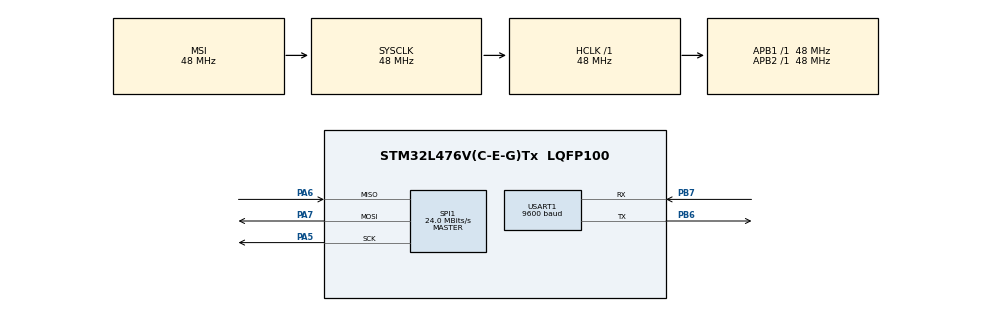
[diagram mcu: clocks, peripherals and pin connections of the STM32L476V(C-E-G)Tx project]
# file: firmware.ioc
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Mcu.Family=STM32L4
Mcu.Name=STM32L476V(C-E-G)Tx
Mcu.Package=LQFP100
NVIC.PriorityGroup=NVIC_PRIORITYGROUP_4
PA5.Mode=Full_Duplex_Master
PA5.Signal=SPI1_SCK
PA6.Mode=Full_Duplex_Master
PA6.Signal=SPI1_MISO
PA7.Mode=Full_Duplex_Master
PA7.Signal=SPI1_MOSI
PB6.Mode=Asynchronous
PB6.Signal=USART1_TX
PB7.Mode=Asynchronous
PB7.Signal=USART1_RX
PH0/OSC_IN.Mode=HSE-External-Oscillator
PH0/OSC_IN.Signal=RCC_OSC_IN
PH1/OSC_OUT.Mode=HSE-External-Oscillator
PH1/OSC_OUT.Signal=RCC_OSC_OUT
ProjectManager.HeapSize=0x200
ProjectManager.StackSize=0x400
ProjectManager.TargetToolchain=TrueSTUDIO
RCC.ADCFreq_Value=32000000
RCC.AHBFreq_Value=48000000
RCC.APB1Freq_Value=48000000
RCC.APB1TimFreq_Value=48000000
RCC.APB2Freq_Value=48000000
RCC.APB2TimFreq_Value=48000000
RCC.CortexFreq_Value=48000000
RCC.HCLKFreq_Value=48000000
RCC.HSE_VALUE=8000000
RCC.HSI_VALUE=16000000
RCC.LSE_VALUE=32768
RCC.MSIClockRange=RCC_MSIRANGE_11
RCC.MSI_VALUE=48000000
RCC.PLLSourceVirtual=RCC_PLLSOURCE_HSE
RCC.PREFETCH_ENABLE=1
RCC.SYSCLKFreq_VALUE=48000000
RCC.USBFreq_Value=32000000
RCC.VCOOutputFreq_Value=64000000
SPI1.CalculateBaudRate=24.0 MBits/s
SPI1.Mode=SPI_MODE_MASTER
USART1.BaudRate=9600
USART1.WordLength=UART_WORDLENGTH_8B
board=STM32L476G-DISCO

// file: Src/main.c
/**
  ******************************************************************************
  * File Name          : main.c
  * Description        : Main program body
  ******************************************************************************
  *
  * COPYRIGHT(c) 2017 STMicroelectronics
  *
  * Redistribution and use in source and binary forms, with or without modification,
  * are permitted provided that the following conditions are met:
  *   1. Redistributions of source code must retain the above copyright notice,
  *      this list of conditions and the following disclaimer.
  *   2. Redistributions in binary form must reproduce the above copyright notice,
  *      this list of conditions and the following disclaimer in the documentation
  *      and/or other materials provided with the distribution.
  *   3. Neither the name of STMicroelectronics nor the names of its contributors
  *      may be used to endorse or promote products derived from this software
  *      without specific prior written permission.
  *
  * THIS SOFTWARE IS PROVIDED BY THE COPYRIGHT HOLDERS AND CONTRIBUTORS "AS IS"
  * AND ANY EXPRESS OR IMPLIED WARRANTIES, INCLUDING, BUT NOT LIMITED TO, THE
  * IMPLIED WARRANTIES OF MERCHANTABILITY AND FITNESS FOR A PARTICULAR PURPOSE ARE
  * DISCLAIMED. IN NO EVENT SHALL THE COPYRIGHT HOLDER OR CONTRIBUTORS BE LIABLE
  * FOR ANY DIRECT, INDIRECT, INCIDENTAL, SPECIAL, EXEMPLARY, OR CONSEQUENTIAL
  * DAMAGES (INCLUDING, BUT NOT LIMITED TO, PROCUREMENT OF SUBSTITUTE GOODS OR
  * SERVICES; LOSS OF USE, DATA, OR PROFITS; OR BUSINESS INTERRUPTION) HOWEVER
  * CAUSED AND ON ANY THEORY OF LIABILITY, WHETHER IN CONTRACT, STRICT LIABILITY,
  * OR TORT (INCLUDING NEGLIGENCE OR OTHERWISE) ARISING IN ANY WAY OUT OF THE USE
  * OF THIS SOFTWARE, EVEN IF ADVISED OF THE POSSIBILITY OF SUCH DAMAGE.
  *
  ******************************************************************************
  */
#include "main.h"
#include "stm32l4xx_hal.h"

/* USER CODE BEGIN Includes */
#include "main_impl.h"
/* USER CODE END Includes */

SPI_HandleTypeDef hspi1;

UART_HandleTypeDef huart1;

/* USER CODE BEGIN PV */
/* Private variables ---------------------------------------------------------*/

/* USER CODE END PV */

void SystemClock_Config(void);
void Error_Handler(void);
static void MX_GPIO_Init(void);
static void MX_USART1_UART_Init(void);
static void MX_SPI1_Init(void);

/* USER CODE BEGIN PFP */
/* Private function prototypes -----------------------------------------------*/

/* USER CODE END PFP */

int main(void)
{

  /* MCU Configuration----------------------------------------------------------*/

  /* Reset of all peripherals, Initializes the Flash interface and the Systick. */
  HAL_Init();

  /* Configure the system clock */
  SystemClock_Config();

  /* Initialize all configured peripherals */
  MX_GPIO_Init();
  MX_USART1_UART_Init();
  MX_SPI1_Init();

  /* USER CODE BEGIN 2 */
  main_init();
  /* USER CODE END 2 */

  /* Infinite loop */
  while (1)
  {

  /* USER CODE BEGIN 3 */
	  main_loop_step();
  }
  /* USER CODE END 3 */

}

/** System Clock Configuration
*/
void SystemClock_Config(void)
{

  RCC_OscInitTypeDef RCC_OscInitStruct;
  RCC_ClkInitTypeDef RCC_ClkInitStruct;
  RCC_PeriphCLKInitTypeDef PeriphClkInit;

    /**Initializes the CPU, AHB and APB busses clocks
    */
  RCC_OscInitStruct.OscillatorType = RCC_OSCILLATORTYPE_MSI;
  RCC_OscInitStruct.MSIState = RCC_MSI_ON;
  RCC_OscInitStruct.MSICalibrationValue = 0;
  RCC_OscInitStruct.MSIClockRange = RCC_MSIRANGE_11;
  RCC_OscInitStruct.PLL.PLLState = RCC_PLL_NONE;
  if (HAL_RCC_OscConfig(&RCC_OscInitStruct) != HAL_OK)
  {
    Error_Handler();
  }

    /**Initializes the CPU, AHB and APB busses clocks
    */
  RCC_ClkInitStruct.ClockType = RCC_CLOCKTYPE_HCLK|RCC_CLOCKTYPE_SYSCLK
                              |RCC_CLOCKTYPE_PCLK1|RCC_CLOCKTYPE_PCLK2;
  RCC_ClkInitStruct.SYSCLKSource = RCC_SYSCLKSOURCE_MSI;
  RCC_ClkInitStruct.AHBCLKDivider = RCC_SYSCLK_DIV1;
  RCC_ClkInitStruct.APB1CLKDivider = RCC_HCLK_DIV1;
  RCC_ClkInitStruct.APB2CLKDivider = RCC_HCLK_DIV1;

  if (HAL_RCC_ClockConfig(&RCC_ClkInitStruct, FLASH_LATENCY_2) != HAL_OK)
  {
    Error_Handler();
  }

  PeriphClkInit.PeriphClockSelection = RCC_PERIPHCLK_USART1;
  PeriphClkInit.Usart1ClockSelection = RCC_USART1CLKSOURCE_PCLK2;
  if (HAL_RCCEx_PeriphCLKConfig(&PeriphClkInit) != HAL_OK)
  {
    Error_Handler();
  }

    /**Configure the main internal regulator output voltage
    */
  if (HAL_PWREx_ControlVoltageScaling(PWR_REGULATOR_VOLTAGE_SCALE1) != HAL_OK)
  {
    Error_Handler();
  }

    /**Configure the Systick interrupt time
    */
  HAL_SYSTICK_Config(HAL_RCC_GetHCLKFreq()/1000);

    /**Configure the Systick
    */
  HAL_SYSTICK_CLKSourceConfig(SYSTICK_CLKSOURCE_HCLK);

  /* SysTick_IRQn interrupt configuration */
  HAL_NVIC_SetPriority(SysTick_IRQn, 0, 0);
}

/* SPI1 init function */
static void MX_SPI1_Init(void)
{

  hspi1.Instance = SPI1;
  hspi1.Init.Mode = SPI_MODE_MASTER;
  hspi1.Init.Direction = SPI_DIRECTION_2LINES;
  hspi1.Init.DataSize = SPI_DATASIZE_4BIT;
  hspi1.Init.CLKPolarity = SPI_POLARITY_LOW;
  hspi1.Init.CLKPhase = SPI_PHASE_1EDGE;
  hspi1.Init.NSS = SPI_NSS_SOFT;
  hspi1.Init.BaudRatePrescaler = SPI_BAUDRATEPRESCALER_2;
  hspi1.Init.FirstBit = SPI_FIRSTBIT_MSB;
  hspi1.Init.TIMode = SPI_TIMODE_DISABLE;
  hspi1.Init.CRCCalculation = SPI_CRCCALCULATION_DISABLE;
  hspi1.Init.CRCPolynomial = 7;
  hspi1.Init.CRCLength = SPI_CRC_LENGTH_DATASIZE;
  hspi1.Init.NSSPMode = SPI_NSS_PULSE_ENABLE;
  if (HAL_SPI_Init(&hspi1) != HAL_OK)
  {
    Error_Handler();
  }

}

/* USART1 init function */
static void MX_USART1_UART_Init(void)
{

  huart1.Instance = USART1;
  huart1.Init.BaudRate = 9600;
  huart1.Init.WordLength = UART_WORDLENGTH_8B;
  huart1.Init.StopBits = UART_STOPBITS_1;
  huart1.Init.Parity = UART_PARITY_NONE;
  huart1.Init.Mode = UART_MODE_TX_RX;
  huart1.Init.HwFlowCtl = UART_HWCONTROL_NONE;
  huart1.Init.OverSampling = UART_OVERSAMPLING_16;
  huart1.Init.OneBitSampling = UART_ONE_BIT_SAMPLE_DISABLE;
  huart1.AdvancedInit.AdvFeatureInit = UART_ADVFEATURE_NO_INIT;
  if (HAL_UART_Init(&huart1) != HAL_OK)
  {
    Error_Handler();
  }

}

/** Configure pins as
        * Analog
        * Input
        * Output
        * EVENT_OUT
        * EXTI
*/
static void MX_GPIO_Init(void)
{

  /* GPIO Ports Clock Enable */
  __HAL_RCC_GPIOH_CLK_ENABLE();
  __HAL_RCC_GPIOA_CLK_ENABLE();
  __HAL_RCC_GPIOB_CLK_ENABLE();

}

void Error_Handler(void)
{
  while(1)
  {
  }
}

/************************ (C) COPYRIGHT STMicroelectronics *****END OF FILE****/
